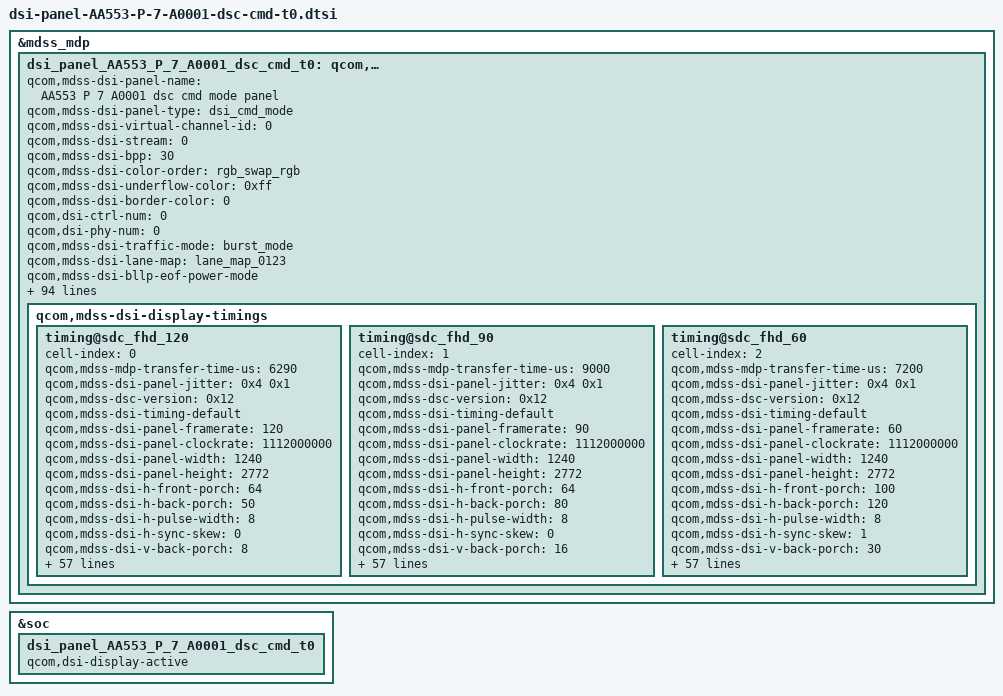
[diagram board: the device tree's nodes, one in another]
&mdss_mdp {
	dsi_panel_AA553_P_7_A0001_dsc_cmd_t0: qcom,mdss_dsi_panel_AA553_P_7_A0001_dsc_cmd_t0 {
		qcom,mdss-dsi-panel-name = "AA553 P 7 A0001 dsc cmd mode panel";
		qcom,mdss-dsi-panel-type = "dsi_cmd_mode";
		qcom,mdss-dsi-virtual-channel-id = <0>;
		qcom,mdss-dsi-stream = <0>;
		qcom,mdss-dsi-bpp = <30>;
		qcom,mdss-dsi-color-order = "rgb_swap_rgb";
		qcom,mdss-dsi-underflow-color = <0xff>;
		qcom,mdss-dsi-border-color = <0>;
		qcom,dsi-ctrl-num = <0>;
		qcom,dsi-phy-num = <0>;
		qcom,mdss-dsi-traffic-mode = "burst_mode";
		qcom,mdss-dsi-lane-map = "lane_map_0123";
		qcom,mdss-dsi-bllp-eof-power-mode;
		qcom,mdss-dsi-bllp-power-mode;
		qcom,mdss-dsi-lane-0-state;
		qcom,mdss-dsi-lane-1-state;
		qcom,mdss-dsi-lane-2-state;
		qcom,mdss-dsi-lane-3-state;
		qcom,mdss-dsi-dma-trigger = "trigger_sw";
		qcom,mdss-dsi-dma-schedule-line = <1>;
		qcom,mdss-dsi-dma-schedule-window = <10>;
		qcom,mdss-dsi-mdp-trigger = "none";
		qcom,mdss-dsi-reset-sequence = <1 2>, <0 5>, <1 25>;
		qcom,mdss-dsi-te-pin-select = <1>;
		qcom,mdss-dsi-te-dcs-command = <1>;
		qcom,mdss-pan-physical-width-dimension = <70>;
		qcom,mdss-pan-physical-height-dimension = <156>;
		qcom,mdss-dsi-init-delay-us = <1000>;
		qcom,mdss-dsi-te-check-enable;
		qcom,mdss-dsi-te-using-te-pin;
		//qcom,mdss-dsi-lp11-init;
		qcom,mdss-dsi-wr-mem-start = <0x2c>;
		qcom,mdss-dsi-wr-mem-continue = <0x3c>;
		qcom,mdss-dsi-panel-jitter = <0x4 0x1>;
		qcom,mdss-dsc-scr-version = <0x1>;
		qcom,mdss-bl-high2bit;
		/* HDR Setting */
		qcom,mdss-dsi-panel-hdr-enabled;
		qcom,mdss-dsi-panel-hdr-color-primaries = <15635 16450 34000 16000 13250 34500 7500 3000>;
		qcom,mdss-dsi-panel-peak-brightness = <5400000>;
		qcom,mdss-dsi-panel-average-brightness = <2000000>;
		qcom,mdss-dsi-panel-blackness-level = <4000>;

		qcom,dynamic-mode-switch-enabled;
		qcom,dynamic-mode-switch-type = "dynamic-resolution-switch-immediate";
		qcom,mdss-dsi-display-timings {
			timing@sdc_fhd_120{
				cell-index = <0>;
				#include "dsi-panel-AA553-P-7-A0001-common-t0.dtsi"
				qcom,mdss-mdp-transfer-time-us = <6290>;
				qcom,mdss-dsi-panel-jitter = <0x4 0x1>;
				qcom,mdss-dsc-version = <0x12>;
				qcom,mdss-dsi-timing-default;
				qcom,mdss-dsi-panel-framerate = <120>;
				qcom,mdss-dsi-panel-clockrate = <1112000000>;
				qcom,mdss-dsi-panel-width = <1240>;
				qcom,mdss-dsi-panel-height = <2772>;

				qcom,mdss-dsi-h-front-porch = <64>;
				qcom,mdss-dsi-h-back-porch = <50>;
				qcom,mdss-dsi-h-pulse-width = <8>;
				qcom,mdss-dsi-h-sync-skew = <0>;
				qcom,mdss-dsi-v-back-porch = <8>;
				qcom,mdss-dsi-v-front-porch = <2>;
				qcom,mdss-dsi-v-pulse-width = <2>;
				qcom,mdss-dsi-h-sync-pulse = <0>;

				qcom,mdss-dsi-h-left-border = <0>;
				qcom,mdss-dsi-h-right-border = <0>;
				qcom,mdss-dsi-v-top-border = <0>;
				qcom,mdss-dsi-v-bottom-border = <0>;

				oplus,ofp-need-to-sync-data-in-aod-unlocking;
				oplus,ofp-aod-off-insert-black-frame = <1>;
				oplus,ofp-aod-off-black-frame-total-time = <42>;

				qcom,mdss-dsi-timing-switch-command = [
					/* Frequence Transition 120hz*/
					15 00 00 20 00 00 02 2F 00
				];
				qcom,mdss-dsi-on-command = [
					/* DVDD Strong */
					39 00 00 40 00 00 06 F0 55 AA 52 08 01
					15 00 00 40 00 00 02 6F 05
					39 00 00 00 00 00 05 C5 15 15 15 DD
					39 00 00 40 00 00 05 FF AA 55 A5 81
					15 00 00 40 00 00 02 6F 19
					15 00 00 40 00 00 02 FB 00
					15 00 00 40 00 00 02 6F 05
					15 00 00 40 00 00 02 FE 3C
					39 00 00 40 00 00 05 FF AA 55 A5 80
					15 00 00 40 00 00 02 6F 1A
					15 00 00 40 00 00 02 F4 55
					39 00 00 40 00 00 05 FF AA 55 A5 83
					15 00 00 40 00 00 02 6F 12
					15 00 00 40 00 00 02 FE 41
					15 00 00 40 00 00 02 5F 00
					15 00 00 40 00 00 02 26 00
					15 00 00 40 00 00 02 26 00
					15 00 00 40 00 00 02 17 10
					39 00 00 40 00 00 05 2A 00 00 04 D7
					39 00 00 40 00 00 05 2B 00 00 0A D3
					15 00 00 40 00 00 02 2F 00 /* Fre 120hz:0x00 90hz:0x01 60hz:0x02*/
					15 00 00 40 00 00 02 35 00
					39 00 00 40 00 00 03 44 00 00
					15 00 00 40 00 00 02 6F 04
					39 00 00 40 00 00 03 51 02 FF
					15 00 00 40 00 00 02 53 20
					39 00 00 00 00 00 03 90 03 03
					/* DSC Setting 10bit3.75 Version1.2 */
					39 00 00 40 00 00 13 91 AB A8 00 0C C2 00 02 37 01 33 00 08 08 BB 07 5F 10 F0
					39 00 00 40 00 00 05 FF AA 55 A5 81
					15 00 00 40 00 00 02 6F 24
					39 00 00 00 00 00 15 FB 00 03 04 55 77 77 77 99 9D 00 00 06 88 9A BB BC DE EF F0 11
					15 00 00 40 00 00 02 6F 0D
					15 00 00 40 00 00 02 FB 80
					39 00 00 40 00 00 05 FF AA 55 A5 81
					15 00 00 40 00 00 02 6F 0E
					15 00 00 40 00 00 02 F5 00
					39 00 00 40 00 00 05 FF AA 55 A5 80
					15 00 00 40 00 00 02 6F 0F
					15 00 00 40 00 00 02 FC 00
					15 00 00 40 00 00 02 6F 09
					39 00 00 40 00 00 03 FC FC F0
					39 00 00 40 00 00 05 FF AA 55 A5 80
					15 00 00 40 00 00 02 6F 0A
					39 00 00 40 00 00 04 F6 70 70 70
					15 00 00 40 00 00 02 6F 0E
					15 00 00 40 00 00 02 F6 60
					39 00 00 40 00 00 05 FF AA 55 A5 80
					15 00 00 40 00 00 02 6F 11
					39 00 00 40 00 00 03 F8 01 7C   /* OSC2=138.6M */
					15 00 00 40 00 00 02 6F 2D
					39 00 00 40 00 00 03 F8 00 FC
					15 00 00 40 00 00 02 6F 01
					15 00 00 40 00 00 02 1F 06
					39 00 00 40 00 00 05 FF AA 55 A5 81
					15 00 00 40 00 00 02 6F 1E
					15 00 00 40 00 00 02 FB 0F
					39 00 00 40 00 00 05 FF AA 55 A5 83
					15 00 00 40 00 00 02 6F 12
					15 00 00 40 00 00 02 FE 41
					39 00 00 40 00 00 05 FF AA 55 A5 80
					15 00 00 40 00 00 02 6F 19
					15 00 00 40 00 00 02 F2 00
					39 00 00 40 00 00 05 FF AA 55 A5 81
					15 00 00 40 00 00 02 6F 02
					15 00 00 40 00 00 02 F9 04
					15 00 00 00 00 00 02 5A 00
					/* OSC tracking 556MHz*/
					39 00 00 40 00 00 06 F0 55 AA 52 08 01
					39 00 00 00 00 00 2A C3 DD 06 22 11 FC 00 06 20 11
					                     FF 00 03 F2 12 05 FC 18 03 F2
					                     12 05 FC 18 03 F2 12 05 FC 18
					                     03 F2 12 05 FC 18 03 F2 12 05
					                     FC 18
					/*Sleep out*/
					05 00 00 00 78 00 01 11
					/*display on*/
					05 00 00 00 00 00 01 29
				];
				qcom,mdss-dsi-default-switch-page-command = [
					/*switch default page*/
					39 00 00 00 00 00 06 F0 55 AA 52 08 00
				];
				qcom,mdss-dsi-off-command=[
					39 00 00 00 46 00 06 F0 55 AA 52 08 00
					05 00 00 00 0A 00 01 28
					05 00 00 00 78 00 01 10
				];
				qcom,mdss-dsi-lp1-command = [
					/* AOD FD Discharge */
					39 00 00 40 00 00 06 F0 55 AA 52 08 00
					15 00 00 40 00 00 02 6F 0C
					39 00 00 40 00 00 03 B5 50 49
					/* AOD Mode ON */
					39 00 00 40 00 00 06 F0 55 AA 52 08 01
					15 00 00 40 00 00 02 6F 01
					15 00 00 40 00 00 02 D2 00
					05 00 00 40 00 00 01 39
					15 00 00 40 00 00 02 65 01
					/* AOD LV Switch */
					15 00 00 40 00 00 02 6F 04
					39 00 00 00 46 00 03 51 02 FF
				];
				qcom,mdss-dsi-nolp-command = [
					/* AOD FD Discharge */
					39 00 00 40 00 00 06 F0 55 AA 52 08 00
					15 00 00 40 00 00 02 6F 0C
					39 00 00 40 00 00 03 B5 4F 49
					/* AOD Mode OFF */
					39 00 00 40 00 00 06 F0 55 AA 52 08 01
					15 00 00 40 00 00 02 6F 01
					15 00 00 40 00 00 02 D2 00
					15 00 00 40 00 00 02 65 00
					05 00 00 00 00 00 01 38
				];
				qcom,mdss-dsi-hbm-off-command = [
					39 00 00 00 09 00 03 51 0D BB
					39 00 00 40 00 00 06 F0 55 AA 52 08 00
					39 00 00 40 00 00 02 6F 01
					39 00 00 00 00 00 02 B5 02
				];
				qcom,mdss-dsi-hbm-on-command = [
					39 00 00 00 00 00 03 51 0F 00
				];
				qcom,mdss-dsi-aod-high-mode-command = [
					/* AOD 50nit */
					15 00 00 00 00 00 02 6F 04
					39 00 00 00 00 00 03 51 02 FF
				];
				qcom,mdss-dsi-aod-low-mode-command = [
					/* AOD 10nit */
					15 00 00 00 00 00 02 6F 04
					39 00 00 00 00 00 03 51 01 FF
				];
				qcom,mdss-dsi-timing-switch-command-state = "dsi_hs_mode";
				qcom,mdss-dsi-on-command-state = "dsi_lp_mode";
				qcom,mdss-dsi-off-command-state = "dsi_hs_mode";
				qcom,mdss-dsi-lp1-command-state = "dsi_lp_mode";
				qcom,mdss-dsi-nolp-command-state = "dsi_lp_mode";
				qcom,mdss-dsi-hbm-on-command-state = "dsi_lp_mode";
				qcom,mdss-dsi-hbm-off-command-state = "dsi_lp_mode";
				qcom,mdss-dsi-default-switch-page-command-state = "dsi_lp_mode";

				qcom,lm-split = <620 620>;
				qcom,compression-mode = "dsc";
				qcom,mdss-dsc-encoders = <2>;
				qcom,mdss-dsc-slice-height = <12>;
				qcom,mdss-dsc-slice-width = <620>;
				qcom,mdss-dsc-slice-per-pkt = <2>;
				qcom,mdss-dsc-bit-per-component = <10>;
				qcom,mdss-dsc-bit-per-pixel = <8>;
				qcom,mdss-dsc-block-prediction-enable;
				qcom,mdss-dsi-panel-id1-command-state = "dsi_lp_mode";
			};
			timing@sdc_fhd_90{
				cell-index = <1>;
				#include "dsi-panel-AA553-P-7-A0001-common-t0.dtsi"
				qcom,mdss-mdp-transfer-time-us = <9000>;
				qcom,mdss-dsi-panel-jitter = <0x4 0x1>;
				qcom,mdss-dsc-version = <0x12>;
				qcom,mdss-dsi-timing-default;
				qcom,mdss-dsi-panel-framerate = <90>;
				qcom,mdss-dsi-panel-clockrate = <1112000000>;
				qcom,mdss-dsi-panel-width = <1240>;
				qcom,mdss-dsi-panel-height = <2772>;

				qcom,mdss-dsi-h-front-porch = <64>;
				qcom,mdss-dsi-h-back-porch = <80>;
				qcom,mdss-dsi-h-pulse-width = <8>;
				qcom,mdss-dsi-h-sync-skew = <0>;
				qcom,mdss-dsi-v-back-porch = <16>;
				qcom,mdss-dsi-v-front-porch = <10>;
				qcom,mdss-dsi-v-pulse-width = <2>;
				qcom,mdss-dsi-h-sync-pulse = <0>;

				qcom,mdss-dsi-h-left-border = <0>;
				qcom,mdss-dsi-h-right-border = <0>;
				qcom,mdss-dsi-v-top-border = <0>;
				qcom,mdss-dsi-v-bottom-border = <0>;

				oplus,ofp-need-to-sync-data-in-aod-unlocking;
				oplus,ofp-aod-off-insert-black-frame = <1>;
				oplus,ofp-aod-off-black-frame-total-time = <45>;

				qcom,mdss-dsi-timing-switch-command = [
					/* Frequence Transition 90hz*/
					15 00 00 20 00 00 02 2F 01
				];
				qcom,mdss-dsi-on-command = [
					/* DVDD Strong */
					39 00 00 40 00 00 06 F0 55 AA 52 08 01
					15 00 00 40 00 00 02 6F 05
					39 00 00 00 00 00 05 C5 15 15 15 DD
					39 00 00 40 00 00 05 FF AA 55 A5 81
					15 00 00 40 00 00 02 6F 19
					15 00 00 40 00 00 02 FB 00
					15 00 00 40 00 00 02 6F 05
					15 00 00 40 00 00 02 FE 3C
					39 00 00 40 00 00 05 FF AA 55 A5 80
					15 00 00 40 00 00 02 6F 1A
					15 00 00 40 00 00 02 F4 55
					39 00 00 40 00 00 05 FF AA 55 A5 83
					15 00 00 40 00 00 02 6F 12
					15 00 00 40 00 00 02 FE 41
					15 00 00 40 00 00 02 5F 00
					15 00 00 40 00 00 02 26 00
					15 00 00 40 00 00 02 26 00
					15 00 00 40 00 00 02 17 10
					39 00 00 40 00 00 05 2A 00 00 04 D7
					39 00 00 40 00 00 05 2B 00 00 0A D3
					15 00 00 40 00 00 02 2F 01 /* Fre 120hz:0x00 90hz:0x01 60hz:0x02*/
					15 00 00 40 00 00 02 35 00
					39 00 00 40 00 00 03 44 00 00
					39 00 00 40 00 00 03 51 0D BB
					15 00 00 40 00 00 02 6F 04
					39 00 00 40 00 00 03 51 02 FF
					15 00 00 40 00 00 02 53 20
					39 00 00 00 00 00 03 90 03 03
					/* DSC Setting 10bit3.75 Version1.2 */
					39 00 00 40 00 00 13 91 AB A8 00 0C C2 00 02 37 01 33 00 08 08 BB 07 5F 10 F0
					39 00 00 40 00 00 05 FF AA 55 A5 81
					15 00 00 40 00 00 02 6F 24
					39 00 00 00 00 00 15 FB 00 03 04 55 77 77 77 99 9D 00 00 06 88 9A BB BC DE EF F0 11
					15 00 00 40 00 00 02 6F 0D
					15 00 00 40 00 00 02 FB 80
					39 00 00 40 00 00 05 FF AA 55 A5 81
					15 00 00 40 00 00 02 6F 0E
					15 00 00 40 00 00 02 F5 00
					39 00 00 40 00 00 05 FF AA 55 A5 80
					15 00 00 40 00 00 02 6F 0F
					15 00 00 40 00 00 02 FC 00
					15 00 00 40 00 00 02 6F 09
					39 00 00 40 00 00 03 FC FC F0
					39 00 00 40 00 00 05 FF AA 55 A5 80
					15 00 00 40 00 00 02 6F 0A
					39 00 00 40 00 00 04 F6 70 70 70
					15 00 00 40 00 00 02 6F 0E
					15 00 00 40 00 00 02 F6 60
					39 00 00 40 00 00 05 FF AA 55 A5 80
					15 00 00 40 00 00 02 6F 11
					39 00 00 40 00 00 03 F8 01 7C   /* OSC2=138.6M */
					15 00 00 40 00 00 02 6F 2D
					39 00 00 40 00 00 03 F8 00 FC
					15 00 00 40 00 00 02 6F 01
					15 00 00 40 00 00 02 1F 06
					39 00 00 40 00 00 05 FF AA 55 A5 81
					15 00 00 40 00 00 02 6F 1E
					15 00 00 40 00 00 02 FB 0F
					39 00 00 40 00 00 05 FF AA 55 A5 83
					15 00 00 40 00 00 02 6F 12
					15 00 00 40 00 00 02 FE 41
					39 00 00 40 00 00 05 FF AA 55 A5 80
					15 00 00 40 00 00 02 6F 19
					15 00 00 40 00 00 02 F2 00
					39 00 00 40 00 00 05 FF AA 55 A5 81
					15 00 00 40 00 00 02 6F 02
					15 00 00 40 00 00 02 F9 04
					15 00 00 00 00 00 02 5A 00
					/* OSC tracking 556MHz*/
					39 00 00 40 00 00 06 F0 55 AA 52 08 01
					39 00 00 00 00 00 2A C3 DD 06 22 11 FC 00 06 20 11
					                     FF 00 03 F2 12 05 FC 18 03 F2
					                     12 05 FC 18 03 F2 12 05 FC 18
					                     03 F2 12 05 FC 18 03 F2 12 05
					                     FC 18
					/*Sleep out*/
					05 00 00 00 78 00 01 11
					/*display on*/
					05 00 00 00 00 00 01 29
				];
				qcom,mdss-dsi-default-switch-page-command = [
					/*switch default page*/
					39 00 00 00 00 00 06 F0 55 AA 52 08 00
				];
				qcom,mdss-dsi-off-command=[
					39 00 00 00 46 00 06 F0 55 AA 52 08 00
					05 00 00 00 0A 00 01 28
					05 00 00 00 78 00 01 10
				];
				qcom,mdss-dsi-lp1-command = [
					/* AOD FD Discharge */
					39 00 00 40 00 00 06 F0 55 AA 52 08 00
					15 00 00 40 00 00 02 6F 0C
					39 00 00 40 00 00 03 B5 50 49
					/* AOD Mode ON */
					39 00 00 40 00 00 06 F0 55 AA 52 08 01
					15 00 00 40 00 00 02 6F 01
					15 00 00 40 00 00 02 D2 00
					05 00 00 40 00 00 01 39
					15 00 00 40 00 00 02 65 01
					/* AOD LV Switch */
					15 00 00 40 00 00 02 6F 04
					39 00 00 00 46 00 03 51 02 FF
				];
				qcom,mdss-dsi-nolp-command = [
					/* AOD FD Discharge */
					39 00 00 40 00 00 06 F0 55 AA 52 08 00
					15 00 00 40 00 00 02 6F 0C
					39 00 00 40 00 00 03 B5 4F 49
					/* AOD Mode OFF */
					39 00 00 40 00 00 06 F0 55 AA 52 08 01
					15 00 00 40 00 00 02 6F 01
					15 00 00 40 00 00 02 D2 00
					15 00 00 40 00 00 02 65 00
					05 00 00 00 00 00 01 38
				];
				qcom,mdss-dsi-hbm-off-command = [
					39 00 00 00 0C 00 03 51 0D BB
					39 00 00 40 00 00 06 F0 55 AA 52 08 00
					39 00 00 40 00 00 02 6F 01
					39 00 00 00 00 00 02 B5 02
				];
				qcom,mdss-dsi-hbm-on-command = [
					39 00 00 00 00 00 03 51 0F 00
				];
				qcom,mdss-dsi-aod-high-mode-command = [
					/* AOD 50nit */
					15 00 00 00 00 00 02 6F 04
					39 00 00 00 00 00 03 51 02 FF
				];
				qcom,mdss-dsi-aod-low-mode-command = [
					/* AOD 10nit */
					15 00 00 00 00 00 02 6F 04
					39 00 00 00 00 00 03 51 01 FF
				];

				qcom,mdss-dsi-timing-switch-command-state = "dsi_hs_mode";
				qcom,mdss-dsi-on-command-state = "dsi_lp_mode";
				qcom,mdss-dsi-off-command-state = "dsi_hs_mode";
				qcom,mdss-dsi-lp1-command-state = "dsi_lp_mode";
				qcom,mdss-dsi-nolp-command-state = "dsi_lp_mode";
				qcom,mdss-dsi-hbm-on-command-state = "dsi_lp_mode";
				qcom,mdss-dsi-hbm-off-command-state = "dsi_lp_mode";
				qcom,mdss-dsi-default-switch-page-command-state = "dsi_lp_mode";

				qcom,lm-split = <620 620>;
				qcom,compression-mode = "dsc";
				qcom,mdss-dsc-encoders = <2>;
				qcom,mdss-dsc-slice-height = <12>;
				qcom,mdss-dsc-slice-width = <620>;
				qcom,mdss-dsc-slice-per-pkt = <2>;
				qcom,mdss-dsc-bit-per-component = <10>;
				qcom,mdss-dsc-bit-per-pixel = <8>;
				qcom,mdss-dsc-block-prediction-enable;
				qcom,mdss-dsi-panel-id1-command-state = "dsi_lp_mode";
			};
			timing@sdc_fhd_60{
				cell-index = <2>;
				#include "dsi-panel-AA553-P-7-A0001-common-t0.dtsi"
				qcom,mdss-mdp-transfer-time-us = <7200>;
				qcom,mdss-dsi-panel-jitter = <0x4 0x1>;
				qcom,mdss-dsc-version = <0x12>;
				qcom,mdss-dsi-timing-default;
				qcom,mdss-dsi-panel-framerate = <60>;
				qcom,mdss-dsi-panel-clockrate = <1112000000>;
				qcom,mdss-dsi-panel-width = <1240>;
				qcom,mdss-dsi-panel-height = <2772>;

				qcom,mdss-dsi-h-front-porch = <100>;
				qcom,mdss-dsi-h-back-porch = <120>;
				qcom,mdss-dsi-h-pulse-width = <8>;
				qcom,mdss-dsi-h-sync-skew = <1>;
				qcom,mdss-dsi-v-back-porch = <30>;
				qcom,mdss-dsi-v-front-porch = <20>;
				qcom,mdss-dsi-v-pulse-width = <2>;
				qcom,mdss-dsi-h-sync-pulse = <0>;

				qcom,mdss-dsi-h-left-border = <0>;
				qcom,mdss-dsi-h-right-border = <0>;
				qcom,mdss-dsi-v-top-border = <0>;
				qcom,mdss-dsi-v-bottom-border = <0>;

				oplus,ofp-need-to-sync-data-in-aod-unlocking;
				oplus,ofp-aod-off-insert-black-frame = <2>;
				oplus,ofp-aod-off-black-frame-total-time = <59>;

				qcom,mdss-dsi-timing-switch-command = [
					/* Frequence Transition 60hz*/
					15 00 00 20 00 00 02 2F 02
				];
				qcom,mdss-dsi-on-command = [
					/* DVDD Strong */
					39 00 00 40 00 00 06 F0 55 AA 52 08 01
					15 00 00 40 00 00 02 6F 05
					39 00 00 00 00 00 05 C5 15 15 15 DD
					39 00 00 40 00 00 05 FF AA 55 A5 81
					15 00 00 40 00 00 02 6F 19
					15 00 00 40 00 00 02 FB 00
					15 00 00 40 00 00 02 6F 05
					15 00 00 40 00 00 02 FE 3C
					39 00 00 40 00 00 05 FF AA 55 A5 80
					15 00 00 40 00 00 02 6F 1A
					15 00 00 40 00 00 02 F4 55
					39 00 00 40 00 00 05 FF AA 55 A5 83
					15 00 00 40 00 00 02 6F 12
					15 00 00 40 00 00 02 FE 41
					15 00 00 40 00 00 02 5F 00
					15 00 00 40 00 00 02 26 00
					15 00 00 40 00 00 02 26 00
					15 00 00 40 00 00 02 17 10
					39 00 00 40 00 00 05 2A 00 00 04 D7
					39 00 00 40 00 00 05 2B 00 00 0A D3
					15 00 00 40 00 00 02 2F 02 /* Fre 120hz:0x00 90hz:0x01 60hz:0x02*/
					15 00 00 40 00 00 02 35 00
					39 00 00 40 00 00 03 44 00 00
					39 00 00 40 00 00 03 51 0D BB
					15 00 00 40 00 00 02 6F 04
					39 00 00 40 00 00 03 51 02 FF
					15 00 00 40 00 00 02 53 20
					39 00 00 00 00 00 03 90 03 03
					/* DSC Setting 10bit3.75 Version1.2 */
					39 00 00 40 00 00 13 91 AB A8 00 0C C2 00 02 37 01 33 00 08 08 BB 07 5F 10 F0
					39 00 00 40 00 00 05 FF AA 55 A5 81
					15 00 00 40 00 00 02 6F 24
					39 00 00 00 00 00 15 FB 00 03 04 55 77 77 77 99 9D 00 00 06 88 9A BB BC DE EF F0 11
					15 00 00 40 00 00 02 6F 0D
					15 00 00 40 00 00 02 FB 80
					39 00 00 40 00 00 05 FF AA 55 A5 81
					15 00 00 40 00 00 02 6F 0E
					15 00 00 40 00 00 02 F5 00
					39 00 00 40 00 00 05 FF AA 55 A5 80
					15 00 00 40 00 00 02 6F 0F
					15 00 00 40 00 00 02 FC 00
					15 00 00 40 00 00 02 6F 09
					39 00 00 40 00 00 03 FC FC F0
					39 00 00 40 00 00 05 FF AA 55 A5 80
					15 00 00 40 00 00 02 6F 0A
					39 00 00 40 00 00 04 F6 70 70 70
					15 00 00 40 00 00 02 6F 0E
					15 00 00 40 00 00 02 F6 60
					39 00 00 40 00 00 05 FF AA 55 A5 80
					15 00 00 40 00 00 02 6F 11
					39 00 00 40 00 00 03 F8 01 7C   /* OSC2=138.6M */
					15 00 00 40 00 00 02 6F 2D
					39 00 00 40 00 00 03 F8 00 FC
					15 00 00 40 00 00 02 6F 01
					15 00 00 40 00 00 02 1F 06
					39 00 00 40 00 00 05 FF AA 55 A5 81
					15 00 00 40 00 00 02 6F 1E
					15 00 00 40 00 00 02 FB 0F
					39 00 00 40 00 00 05 FF AA 55 A5 83
					15 00 00 40 00 00 02 6F 12
					15 00 00 40 00 00 02 FE 41
					39 00 00 40 00 00 05 FF AA 55 A5 80
					15 00 00 40 00 00 02 6F 19
					15 00 00 40 00 00 02 F2 00
					39 00 00 40 00 00 05 FF AA 55 A5 81
					15 00 00 40 00 00 02 6F 02
					15 00 00 40 00 00 02 F9 04
					15 00 00 00 00 00 02 5A 00
					/* OSC tracking 556MHz*/
					39 00 00 40 00 00 06 F0 55 AA 52 08 01
					39 00 00 00 00 00 2A C3 DD 06 22 11 FC 00 06 20 11
					                     FF 00 03 F2 12 05 FC 18 03 F2
					                     12 05 FC 18 03 F2 12 05 FC 18
					                     03 F2 12 05 FC 18 03 F2 12 05
					                     FC 18
					/*Sleep out*/
					05 00 00 00 78 00 01 11
					/*display on*/
					05 00 00 00 00 00 01 29
				];
				qcom,mdss-dsi-default-switch-page-command = [
					/*switch default page*/
					39 00 00 00 00 00 06 F0 55 AA 52 08 00
				];
				qcom,mdss-dsi-off-command=[
					39 00 00 00 46 00 06 F0 55 AA 52 08 00
					05 00 00 00 0A 00 01 28
					05 00 00 00 78 00 01 10
				];
				qcom,mdss-dsi-lp1-command = [
					/* AOD FD Discharge */
					39 00 00 40 00 00 06 F0 55 AA 52 08 00
					15 00 00 40 00 00 02 6F 0C
					39 00 00 40 00 00 03 B5 50 49
					/* AOD Mode ON */
					39 00 00 40 00 00 06 F0 55 AA 52 08 01
					15 00 00 40 00 00 02 6F 01
					15 00 00 40 00 00 02 D2 00
					05 00 00 40 00 00 01 39
					15 00 00 40 00 00 02 65 01
					/* AOD LV Switch */
					15 00 00 40 00 00 02 6F 04
					39 00 00 00 46 00 03 51 02 FF
				];
				qcom,mdss-dsi-nolp-command = [
					/* AOD FD Discharge */
					39 00 00 40 00 00 06 F0 55 AA 52 08 00
					15 00 00 40 00 00 02 6F 0C
					39 00 00 40 00 00 03 B5 4F 49
					/* AOD Mode OFF */
					39 00 00 40 00 00 06 F0 55 AA 52 08 01
					15 00 00 40 00 00 02 6F 01
					15 00 00 40 00 00 02 D2 00
					15 00 00 40 00 00 02 65 00
					05 00 00 00 00 00 01 38
				];
				qcom,mdss-dsi-hbm-off-command = [
					39 00 00 00 00 00 03 51 0D BB
				];
				qcom,mdss-dsi-hbm-on-command = [
					39 00 00 00 00 00 03 51 0F 00
				];
				qcom,mdss-dsi-aod-high-mode-command = [
					/* AOD 50nit */
					15 00 00 00 00 00 02 6F 04
					39 00 00 00 00 00 03 51 02 FF
				];
				qcom,mdss-dsi-aod-low-mode-command = [
					/* AOD 10nit */
					15 00 00 00 00 00 02 6F 04
					39 00 00 00 00 00 03 51 01 FF
				];

				qcom,mdss-dsi-timing-switch-command-state = "dsi_hs_mode";
				qcom,mdss-dsi-on-command-state = "dsi_lp_mode";
				qcom,mdss-dsi-off-command-state = "dsi_hs_mode";
				qcom,mdss-dsi-lp1-command-state = "dsi_lp_mode";
				qcom,mdss-dsi-nolp-command-state = "dsi_lp_mode";
				qcom,mdss-dsi-hbm-on-command-state = "dsi_lp_mode";
				qcom,mdss-dsi-hbm-off-command-state = "dsi_lp_mode";
				qcom,mdss-dsi-default-switch-page-command-state = "dsi_lp_mode";

				qcom,lm-split = <620 620>;
				qcom,compression-mode = "dsc";
				qcom,mdss-dsc-encoders = <2>;
				qcom,mdss-dsc-slice-height = <12>;
				qcom,mdss-dsc-slice-width = <620>;
				qcom,mdss-dsc-slice-per-pkt = <2>;
				qcom,mdss-dsc-bit-per-component = <10>;
				qcom,mdss-dsc-bit-per-pixel = <8>;
				qcom,mdss-dsc-block-prediction-enable;
				qcom,mdss-dsi-panel-id1-command-state = "dsi_lp_mode";
			};
		};
	};
};

&soc {
	dsi_panel_AA553_P_7_A0001_dsc_cmd_t0 {
		qcom,dsi-display-active;
	};
};

&dsi_panel_AA553_P_7_A0001_dsc_cmd_t0 {
	qcom,ulps-enabled;
	qcom,dsi-select-clocks = "pll_byte_clk0", "pll_dsi_clk0";

	qcom,mdss-dsi-display-timings {
		timing@sdc_fhd_120 { /* FHD+ 120hz 556Mhz 1112Mbps */
			qcom,mdss-dsi-panel-phy-timings = [00 24 0A 0A 1A 18 0A 0A 09 02 04 00 1E 0F];
			qcom,display-topology = <1 1 1>,<2 2 1>;
			qcom,default-topology-index = <1>;
		};
		timing@sdc_fhd_90 { /* FHD+ 90hz 556Mhz 1112Mbps */
			qcom,mdss-dsi-panel-phy-timings = [00 24 0A 0A 1A 18 0A 0A 09 02 04 00 1E 0F];
			qcom,display-topology = <1 1 1>,<2 2 1>;
			qcom,default-topology-index = <1>;
		};
		timing@sdc_fhd_60 { /* FHD+ 60hz 556Mhz 1112Mbps */
			qcom,mdss-dsi-panel-phy-timings = [00 24 0A 0A 1A 18 0A 0A 09 02 04 00 1E 0F];
			qcom,display-topology = <1 1 1>,<2 2 1>;
			qcom,default-topology-index = <1>;
		};
	};
};
&dsi_panel_AA553_P_7_A0001_dsc_cmd_t0 {
	qcom,panel_voltage_vddi_name = "vddio";
	qcom,panel_voltage_vddi = <0 1800000 1850000 1950000>;
	qcom,panel_voltage_vddr_name = "vddio";
	qcom,panel_voltage_vddr = <1 1800000 1850000 1950000>;
};

&dsi_panel_AA553_P_7_A0001_dsc_cmd_t0 {
	oplus,color_vivid_status;
	oplus,color_srgb_status;
	oplus,color_softiris_status;
	oplus,color_dual_brightness_status;
	oplus,color_2nit_status;
	oplus,color_oplus_calibrate_status;
	oplus,color_samsung_status;
	oplus,color_loading_status;
	oplus,color_nature_profession_status;
	oplus,mdss-dsi-panel-type = <2>;

	/* HARDWARE CONFIG */
	qcom,panel-supply-entries = <&oplus_dsi_panel_custom_pwr_supply>;
	qcom,mdss-dsi-panel-controller = <&mdss_dsi0>;
	qcom,platform-te-gpio = <&tlmm 77 0>;
	qcom,dynamic-te-gpio = <&tlmm 76 0>;
	qcom,platform-reset-gpio = <&tlmm 79 0>;
	qcom,platform-panel-vout-gpio = <&tlmm 116 0>;

	/* BRIGHTNESS CONFIG */
	qcom,mdss-dsi-bl-pmic-control-type = "bl_ctrl_dcs";
	qcom,bl-dsc-cmd-state = "dsi_hs_mode";
	qcom,bl-update-flag = "delay_until_first_frame";
	qcom,mdss-dsi-bl-inverted-dbv;
	qcom,mdss-dsi-bl-min-level = <1>;
	qcom,mdss-dsi-bl-max-level = <3999>;
	qcom,mdss-brightness-max-level = <3999>;
	oplus,dsi-bl-normal-max-level = <3238>;
	oplus,dsi-brightness-normal-max-level = <3238>;
	oplus,dsi-dc-backlight-threshold = <1960>;
	oplus,dsi-brightness-default-level = <1638>;
	oplus,dsi_demura2_offset_support;

	/* FACTORY CONFIG */
	oplus,mdss-dsi-vendor-name = "A0001";
	oplus,mdss-dsi-manufacture = "P_7";
	oplus,color_vivid_status;
	oplus,color_srgb_status;
	oplus,color_softiris_status;
	oplus,color_dual_brightness_status;

	/* serial num config */
	oplus,dsi-serial-number-enabled;
	oplus,dsi-serial-number-index= <0>;
	oplus,dsi-serial-number-reg= <0xA3>;
	oplus,dsi-serial-number-read-count= <7>;

	/* ESD CONFIG */
	qcom,esd-check-enabled;
	qcom,mdss-dsi-panel-status-check-mode = "reg_read";
	qcom,mdss-dsi-panel-status-command = [
		06 00 00 00 00 00 01 0A
		06 00 00 00 00 00 01 91
		06 00 00 00 00 00 01 03
	];
	qcom,mdss-dsi-panel-status-command-state = "dsi_lp_mode";
	qcom,mdss-dsi-panel-status-value = <0x9C 0xAB 0x00>;
	qcom,mdss-dsi-panel-status-read-length = <1 1 1>;
	oplus,mdss-dsi-panel-status-match-modes = <0x00000000>;

	/* OPLUS FEATURES CONFIG */
	/* adfr config */
	oplus,adfr-config = <0x0>;

	/* temp-compensation config */
	oplus,temp-compensation-config = <0x0>;

	/* ofp config */
	oplus,ofp-fp-type = <0x08>;
	oplus,ofp-longrui-aod-config = <0x06>;
	oplus,ofp-need-to-wait-data-before-aod-on;
};
